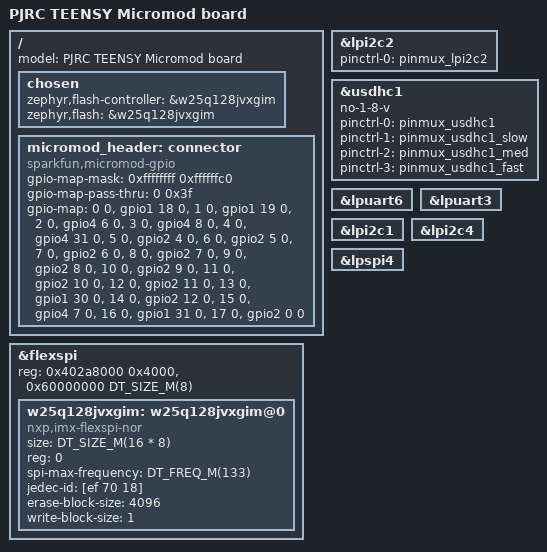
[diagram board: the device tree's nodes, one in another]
/*
 * Copyright (c) 2020, Bernhard Kraemer
 *
 * SPDX-License-Identifier: Apache-2.0
 */

#include "teensy40.dts"

/ {
	model = "PJRC TEENSY Micromod board";

	chosen {
		zephyr,flash-controller = &w25q128jvxgim;
		zephyr,flash = &w25q128jvxgim;
	};

	micromod_header: connector {
		compatible = "sparkfun,micromod-gpio";
		#gpio-cells = <2>;
		gpio-map-mask = <0xffffffff 0xffffffc0>;
		gpio-map-pass-thru = <0 0x3f>;
		gpio-map = <0 0 &gpio1 18 0>,	/* A0         MMOD 34 */
			   <1 0 &gpio1 19 0>,		/* A1         MMOD 38 */
			   <2 0 &gpio4 6 0>,			/* D0         MMOD 10 */
			   <3 0 &gpio4 8 0>,			/* D1/CAM_TRIG MMOD 18 */
			   <4 0 &gpio4 31 0>,		/* I2C_INT#   MMOD 16 */
			   <5 0 &gpio2 4 0>,			/* G0/BUS0    MMOD 40 */
			   <6 0 &gpio2 5 0>,			/* G1/BUS1    MMOD 42 */
			   <7 0 &gpio2 6 0>,			/* G2/BUS2    MMOD 44 */
			   <8 0 &gpio2 7 0>,			/* G3/BUS3    MMOD 46 */
			   <9 0 &gpio2 8 0>,			/* G4/BUS4    MMOD 48 */
			   <10 0 &gpio2 9 0>,		/* G5/BUS5    MMOD 73 */
			   <11 0 &gpio2 10 0>,		/* G6/BUS6    MMOD 71 */
			   <12 0 &gpio2 11 0>,		/* G7/BUS7    MMOD 69 */
			   <13 0 &gpio1 30 0>,		/* G8         MMOD 67 */
			   <14 0 &gpio2 12 0>,		/* G9/ADC_D-/ MMOD 65 */
			   <15 0 &gpio4 7 0>,		/* G10/ADC_D+ MMOD 63 */
			   <16 0 &gpio1 31 0>,		/* G11/SWO    MMOD  8 */
			   <17 0 &gpio2 0 0>;		/* SPI_CS     MMOD 55 */
	};
};

/delete-node/ &w25q16jvuxim;

&flexspi {
	status = "okay";
	reg = <0x402a8000 0x4000>, <0x60000000 DT_SIZE_M(8)>;

	/* WINBOND flash memory*/
	w25q128jvxgim: w25q128jvxgim@0 {
		compatible = "nxp,imx-flexspi-nor";
		size = <DT_SIZE_M(16 * 8)>;
		reg = <0>;
		spi-max-frequency = <DT_FREQ_M(133)>;
		status = "okay";
		jedec-id = [ef 70 18];

		erase-block-size = <4096>;
		write-block-size = <1>;
	};
};

&lpi2c2 {
	pinctrl-0 = <&pinmux_lpi2c2>;
	pinctrl-names = "default";
};

&usdhc1 {
	no-1-8-v;
	pinctrl-0 = <&pinmux_usdhc1>;
	pinctrl-1 = <&pinmux_usdhc1_slow>;
	pinctrl-2 = <&pinmux_usdhc1_med>;
	pinctrl-3 = <&pinmux_usdhc1_fast>;
	pinctrl-names = "default", "slow", "med", "fast";
};

// Sparkfun Micromod compatible pins
micromod_1_uart: &lpuart6 {};

micromod_2_uart: &lpuart3 {};

micromod_0_i2c: &lpi2c1 {};

micromod_1_i2c: &lpi2c4 {};

micromod_0_spi: &lpspi4 {};
